# GD32E53x register map
File version: 1.0
CPU: CM33 r0p4, little endian, MPU, FPU, 4 interrupt priority bits
Registers are 32-bit, read-write, reset 0x0 unless marked. A register's access mark holds for its fields unless they carry their own. Offsets are from the block's base; [hi:lo] are bit positions.

## I2C0 — Inter-integrated circuit interface
Base 0x40005400
Same registers: I2C1 0x40005800, I2C2 0x4000C000
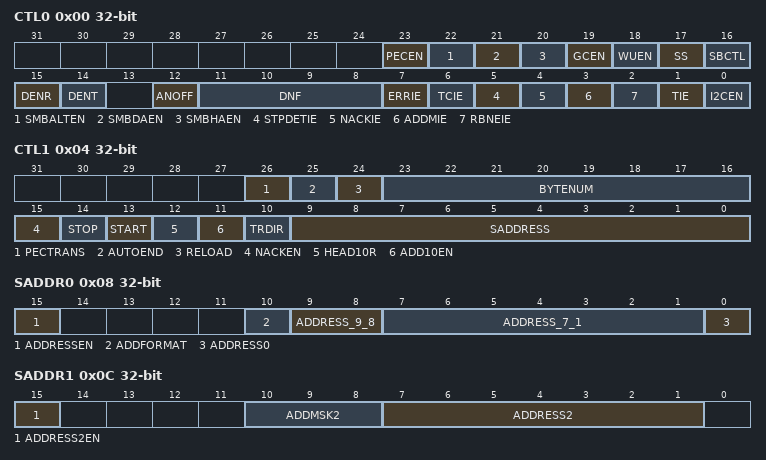
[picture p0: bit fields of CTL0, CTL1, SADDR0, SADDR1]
0x00 CTL0 — Control register 0
  [23] PECEN — PEC Calculation Switch
  [22] SMBALTEN — SMBus Alert enable
  [21] SMBDAEN — SMBus device default address enable
  [20] SMBHAEN — SMBus host address enable
  [19] GCEN — Whether or not to response to a General Call (0x00)
  [18] WUEN — Wakeup from Deep-sleep mode and Deep-sleep mode 1 enable (only support in I2C2)
  [17] SS — Whether to stretch SCL low when data is not ready in slave mode.
  [16] SBCTL — Slave byte control
  [15] DENR — DMA enable for reception
  [14] DENT — DMA enable for transmission
  [12] ANOFF — Analog noise filter disable
  [11:8] DNF — Digital noise filter
  [7] ERRIE — Error interrupt enable
  [6] TCIE — Transfer complete interrupt enable
  [5] STPDETIE — Stop detection interrupt enable
  [4] NACKIE — Not acknowledge received interrupt enable
  [3] ADDMIE — Address match interrupt enable in slave mode
  [2] RBNEIE — Receive interrupt enable
  [1] TIE — Transmit interrupt enable
  [0] I2CEN — I2C peripheral enable
0x04 CTL1 — Control register 1
  [26] PECTRANS — PEC Transfer
  [25] AUTOEND — Automatic end mode in master mode
  [24] RELOAD — Reload mode
  [23:16] BYTENUM — Number of bytes to be transferred
  [15] NACKEN — Generate NACK in slave mode
  [14] STOP — Generate a STOP signal on I2C bus
  [13] START — Generate a START signal on I2C bus
  [12] HEAD10R — 10-bit address header executes read direction only in master receive mode
  [11] ADD10EN — 10-bit addressing mode enable in master mode
  [10] TRDIR — Transfer direction in master mode
  [9:0] SADDRESS — Slave address to be sent
0x08 SADDR0 — Slave address register 0
  [15] ADDRESSEN — I2C address enable
  [10] ADDFORMAT — Address mode for the I2C slave
  [9:8] ADDRESS_9_8 — Highest two bits of a 10-bit address
  [7:1] ADDRESS_7_1 — 7-bit address or bits 7:1 of a 10-bit address
  [0] ADDRESS0 — Bit 0 of a 10-bit address
0x0C SADDR1 — Slave address register 1
  [15] ADDRESS2EN — Second I2C address enable
  [10:8] ADDMSK2 — ADDRESS2[7:1] mask
  [7:1] ADDRESS2 — Second I2C address for the slave
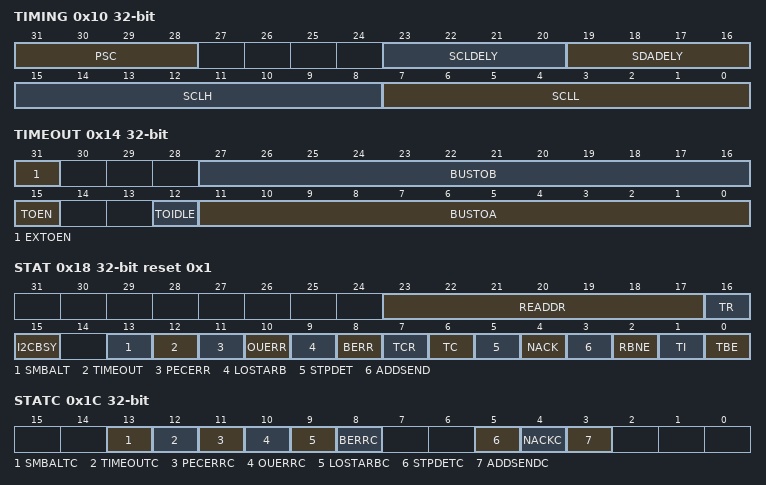
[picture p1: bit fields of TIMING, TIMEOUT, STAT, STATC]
0x10 TIMING
  [31:28] PSC — Timing prescaler
  [23:20] SCLDELY — Data setup time
  [19:16] SDADELY — Data hold time
  [15:8] SCLH — SCL high period
  [7:0] SCLL — SCL low period
0x14 TIMEOUT
  [31] EXTOEN — Extended clock timeout detection enable
  [27:16] BUSTOB — Bus timeout B
  [15] TOEN — Clock timeout detection enable
  [12] TOIDLE — Idle clock timeout detection
  [11:0] BUSTOA — Bus timeout A
0x18 STAT access per field reset 0x1 — Status register
  [23:17] READDR ro — Received match address in slave mode
  [16] TR ro — Whether the I2C is a transmitter or a receiver in slave mode
  [15] I2CBSY ro — Busy flag
  [13] SMBALT ro — SMBus Alert
  [12] TIMEOUT ro — TIMEOUT flag.
  [11] PECERR ro — PEC error
  [10] OUERR ro — Overrun/Underrun error in slave mode
  [9] LOSTARB ro — Arbitration Lost
  [8] BERR ro — Bus error
  [7] TCR ro — Transfer complete reload
  [6] TC ro — Transfer complete in master mode
  [5] STPDET ro — STOP signal detected in slave mode
  [4] NACK ro — Not Acknowledge flag
  [3] ADDSEND ro — Address received matches in slave mode.
  [2] RBNE ro — I2C_RDATA is not empty during receiving
  [1] TI rw — Transmit interrupt
  [0] TBE rw — I2C_TDATA is empty during transmitting
0x1C STATC wo — Status clear register
  [13] SMBALTC — SMBus alert flag clear.
  [12] TIMEOUTC — TIMEOUT flag clear.
  [11] PECERRC — PEC error flag clear.
  [10] OUERRC — Overrun/Underrun flag clear.
  [9] LOSTARBC — Arbitration Lost flag clear.
  [8] BERRC — Bus error flag clear.
  [5] STPDETC — STPDET flag clear
  [4] NACKC — Not Acknowledge flag clear
  [3] ADDSENDC — ADDSEND flag clear
0x20 PEC ro
  [7:0] PECV — Packet Error Checking Value that calculated by hardware when PEC is enabled.
0x24 RDATA ro — Receive data register
  [7:0] RDATA — Receive data value
0x28 TDATA — Transmit data register
  [7:0] TDATA — Transmit data value
0x90 CTL2 reset 0xFE00 — Control register 2
  [15:9] ADDM — Defines which bits of ADDRESS[7:1] are compared with an incoming address byte, and which bits are ignored. Any bit set to 1 in ADDM[6:0] enables comparisons with the corresponding bit in ADDRESS[7:1]. Bits set to 0 are ignored (can be either 0 or 1 in the incoming address).
